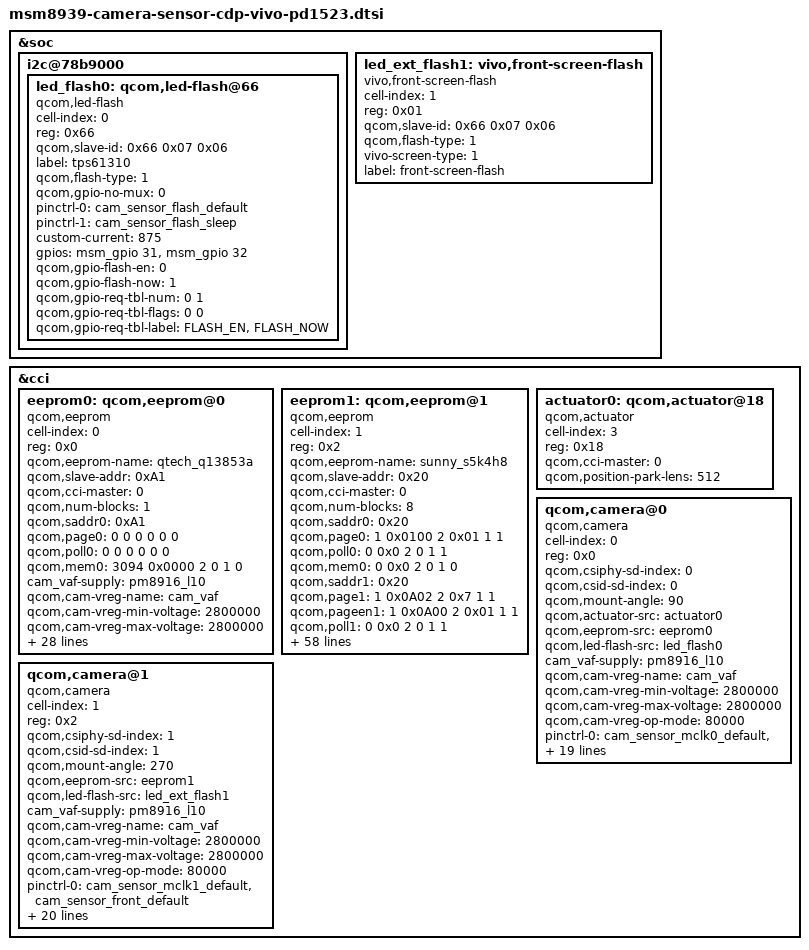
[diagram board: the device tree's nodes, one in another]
/*
 * Copyright (c) 2014, The Linux Foundation. All rights reserved.
 *
 * This program is free software; you can redistribute it and/or modify
 * it under the terms of the GNU General Public License version 2 and
 * only version 2 as published by the Free Software Foundation.
 *
 * This program is distributed in the hope that it will be useful,
 * but WITHOUT ANY WARRANTY; without even the implied warranty of
 * MERCHANTABILITY or FITNESS FOR A PARTICULAR PURPOSE.  See the
 * GNU General Public License for more details.
 */

&soc {
	i2c@78b9000 { /* BLSP1 QUP5 */
		status = "ok";
		led_flash0: qcom,led-flash@66 {
		    cell-index = <0>;
			reg = <0x66>;
			qcom,slave-id = <0x66 0x07 0x06>;
			compatible = "qcom,led-flash";
			label = "tps61310";
			/*qcom,flash-name = "tps61310";*/
			qcom,flash-type = <1>;
			qcom,gpio-no-mux = <0>;
			pinctrl-names = "cam_flash_default", "cam_flash_suspend";
			pinctrl-0 = <&cam_sensor_flash_default>;
			pinctrl-1 = <&cam_sensor_flash_sleep>;
			
			custom-current = <875>;
			gpios = <&msm_gpio 31 0>,<&msm_gpio 32 0>;
	        	qcom,gpio-flash-en = <0>;
			qcom,gpio-flash-now = <1>;
			qcom,gpio-req-tbl-num = <0 1>;
			qcom,gpio-req-tbl-flags = <0 0>;
			qcom,gpio-req-tbl-label = "FLASH_EN",
				"FLASH_NOW";
	    };	
	};
	led_ext_flash1: vivo,front-screen-flash {
		cell-index = <1>;
		reg = <0x01>;
        qcom,slave-id = <0x66 0x07 0x06>;
        qcom,flash-type = <1>;
        vivo-screen-type = <1>;
		compatible = "vivo,front-screen-flash";
		label = "front-screen-flash";
	};	
};


&cci {

	//add by panchenjun 
	
eeprom0: qcom,eeprom@0{
		cell-index = <0>;
		reg = <0x0>; 
		qcom,eeprom-name = "qtech_q13853a"; 
		compatible = "qcom,eeprom";
		qcom,slave-addr = <0xA1>; 
		qcom,cci-master = <0>;
		qcom,num-blocks = <1>; 
		qcom,saddr0 = <0xA1>;
		qcom,page0 = <0 0 0 0 0 0>;
		qcom,poll0 = <0 0 0 0 0 0>;
		qcom,mem0 = <3094 0x0000 2 0 1 0>;//read module info

		cam_vaf-supply = <&pm8916_l10>;//not use,use gpio1;PS:vana also use gpio1	
		qcom,cam-vreg-name = "cam_vaf";		
		qcom,cam-vreg-min-voltage = <2800000>;		
		qcom,cam-vreg-max-voltage = <2800000>;		
		qcom,cam-vreg-op-mode = <100000>;		
		qcom,gpio-no-mux = <0>; 
		
		pinctrl-names = "cam_default", "cam_suspend";		
		pinctrl-0 = <&cam_sensor_mclk0_default	&cam_sensor_rear_default>;		
		pinctrl-1 = <&cam_sensor_mclk0_sleep 	&cam_sensor_rear_sleep>;
		
		gpios = <&msm_gpio 26 0>,
			<&msm_gpio 35 0>,
			<&msm_gpio 76 0>,
			<&msm_gpio 17 0>,
			<&msm_gpio 77 0>;
		qcom,gpio-reset = <1>;
		qcom,gpio-vana = <2>;
		qcom,gpio-vdig = <3>;
		qcom,gpio-vio = <4>;
		qcom,gpio-req-tbl-num = <0 1 2 3 4>;
		qcom,gpio-req-tbl-flags = <1 0 0 0 0>;
		qcom,gpio-req-tbl-label = "CAMIF_MCLK",
			"CAM_RESET",
			"CAM_VANA",
			"CAM_VDIG",
			"CAM_VIO";
		qcom,sensor-position = <0>;
		qcom,sensor-mode = <0>;
		qcom,cam-power-seq-delay = <5 5 5 5 10 >; 
		qcom,cam-power-seq-type = "sensor_gpio", "sensor_gpio", "sensor_vreg", "sensor_gpio", "sensor_clk";
		qcom,cam-power-seq-val = "sensor_gpio_vana",  "sensor_gpio_vio", "cam_vaf", "sensor_gpio_reset", "sensor_cam_mclk";
		qcom,cam-power-seq-cfg-val = <1 1  1 1 24000000>; 
		
		status = "ok";
		clocks = <&clock_gcc clk_mclk0_clk_src>,				
			<&clock_gcc clk_gcc_camss_mclk0_clk>;		
		clock-names = "cam_src_clk", "cam_clk";
			
	}; 	
	//add end
	//lianhua add for sub camera s5k4h8 
	eeprom1: qcom,eeprom@1 { 
		cell-index = <1>; 
		reg = <0x2>; 
		qcom,eeprom-name = "sunny_s5k4h8"; 
		compatible = "qcom,eeprom"; 

		qcom,slave-addr = <0x20>; 
		qcom,cci-master = <0>; 
		qcom,num-blocks = <8>; 
	

		qcom,saddr0 = <0x20>;
		qcom,page0 = <1 0x0100 2 0x01 1 1>;
		qcom,poll0= <0 0x0 2 0 1 1>;
		qcom,mem0 = <0 0x0 2 0 1 0>;

		qcom,saddr1 = <0x20>;
		qcom,page1 = <1 0x0A02 2 0x7 1 1>;  //page 0 module info
		qcom,pageen1 = <1 0x0A00 2 0x01 1 1>;
		qcom,poll1 = <0 0x0 2 0 1 1>;
		qcom,mem1= <59 0x0A09 2 0 1 0>;

		qcom,saddr2 = <0x20>;
		qcom,page2 = <1 0x0A02 2 0x8 1 1>;  //page 0 module info
		qcom,pageen2 = <1 0x0A00 2 0x01 1 1>;
		qcom,poll2= <0 0x0 2 0 1 1>;
		qcom,mem2= <64 0x0A04 2 0 1 0>;


		qcom,saddr3 = <0x20>;
		qcom,page3= <1 0x0A02 2 0x9 1 1>;  //page 0 module info
		qcom,pageen3 = <1 0x0A00 2 0x01 1 1>;
		qcom,poll3 = <0 0x0 2 0 1 1>;
		qcom,mem3 = <64 0x0A04 2 0 1 0>;

		
		qcom,saddr4 = <0x20>;
		qcom,page4 = <1 0x0A02 2 0xa 1 1>;  //page 0 module info
		qcom,pageen4 = <1 0x0A00 2 0x01 1 1>;
		qcom,poll4 = <0 0x0 2 0 1 1>;
		qcom,mem4 = <64 0x0A04 2 0 1 0>;

		
		qcom,saddr5 = <0x20>;
		qcom,page5 = <1 0x0A02 2 0xb 1 1>;  //page 0 module info
		qcom,pageen5 = <1 0x0A00 2 0x01 1 1>;
		qcom,poll5 = <0 0x0 2 0 1 1>;
		qcom,mem5 = <64 0x0A04 2 0 1 0>;

		
		qcom,saddr6 = <0x20>;
		qcom,page6 = <1 0x0A02 2 0xc 1 1>;  //page 0 module info
		qcom,pageen6 = <1 0x0A00 2 0x01 1 1>;
		qcom,poll6 = <0 0x0 2 0 1 1>;
		qcom,mem6 = <44 0x0A04 2 0 1 0>;

		
		qcom,saddr7 = <0x20>;
		qcom,page7 = <1 0x0A02 2 0xf 1 1>;  //page 0 module info
		qcom,pageen7 = <1 0x0A00 2 0x01 1 1>;
		qcom,poll7 = <0 0x0 2 0 1 1>;
		qcom,mem7 = <64 0x0A04 2 0 1 0>;
		
		pinctrl-names = "cam_default", "cam_suspend";
		pinctrl-0 = <&cam_sensor_mclk1_default &cam_sensor_front_default
				>;
		pinctrl-1 = <&cam_sensor_mclk1_sleep &cam_sensor_front_sleep
				>;
		gpios = <&msm_gpio 27 0>,
			<&msm_gpio 28 0>,
			<&msm_gpio 33 0>,
			<&msm_gpio 76 0>,
			<&msm_gpio 0 0>,
			<&msm_gpio 77 0>;
		qcom,gpio-reset = <1>;
		qcom,gpio-standby = <2>;
		qcom,gpio-vana = <3>;
		qcom,gpio-vdig = <4>;
		qcom,gpio-vio = <5>;
		qcom,gpio-req-tbl-num = <0 1 2 3 4 5>;
		qcom,gpio-req-tbl-flags = <1 0 0 0 0 0>;
		qcom,gpio-req-tbl-label = "CAMIF_MCLK",
			"CAM_RESET",
			"CAM_STANDBY",
			"CAM_VANA1",
			"CAM_VDIG",
			"CAM_VIO";
		
		qcom,cam-power-seq-type ="sensor_gpio", "sensor_gpio",	"sensor_gpio", 
		"sensor_gpio","sensor_clk"; 
		qcom,cam-power-seq-val ="sensor_gpio_vio", "sensor_gpio_vana","sensor_gpio_vdig",  
		"sensor_gpio_reset","sensor_cam_mclk"; 
		
		qcom,cam-power-seq-cfg-val = <1 1 1 1 24000000 >; 
		qcom,cam-power-seq-delay = <5 5 5 5 5 >; 
		
		status = "ok";
		qcom,mclk-24000000;
		clocks = <&clock_gcc clk_mclk1_clk_src>,
				<&clock_gcc clk_gcc_camss_mclk1_clk>;
		clock-names = "cam_src_clk", "cam_clk";

	}; 	


	actuator0: qcom,actuator@18 {
		cell-index = <3>;
		reg = <0x18>;
		compatible = "qcom,actuator";
		qcom,cci-master = <0>;
		qcom,position-park-lens = <512>;
		/*
		cam_vaf-supply = <&pm8916_l10>;
		qcom,cam-vreg-name = "cam_vaf";
		qcom,cam-vreg-min-voltage = <2800000>;
		qcom,cam-vreg-max-voltage = <2800000>;
		qcom,cam-vreg-op-mode = <80000>;
		*/
	};


	qcom,camera@0{
		cell-index = <0>;
		compatible = "qcom,camera";
		reg = <0x0>;
		qcom,csiphy-sd-index = <0>;
		qcom,csid-sd-index = <0>;
		qcom,mount-angle = <90>;
		qcom,actuator-src = <&actuator0>;
		qcom,eeprom-src = <&eeprom0>; 
		qcom,led-flash-src = <&led_flash0>;
		cam_vaf-supply = <&pm8916_l10>;
		qcom,cam-vreg-name = "cam_vaf";
		qcom,cam-vreg-min-voltage = <2800000>;
		qcom,cam-vreg-max-voltage = <2800000>;
		qcom,cam-vreg-op-mode = <80000>;
		pinctrl-names = "cam_default", "cam_suspend";
		pinctrl-0 = <&cam_sensor_mclk0_default
					&cam_sensor_rear_default>;
		pinctrl-1 = <&cam_sensor_mclk0_sleep &cam_sensor_rear_sleep>;
		gpios = <&msm_gpio 26 0>,
			<&msm_gpio 35 0>,
			<&msm_gpio 76 0>,
			<&msm_gpio 17 0>,
			<&msm_gpio 77 0>;
		qcom,gpio-reset = <1>;
		qcom,gpio-vana = <2>;
		qcom,gpio-vdig = <3>;
		qcom,gpio-vio = <4>;
		qcom,gpio-req-tbl-num = <0 1 2 3 4>;
		qcom,gpio-req-tbl-flags = <1 0 0 0 0>;
		qcom,gpio-req-tbl-label = "CAMIF_MCLK",
			"CAM_RESET",
			"CAM_VANA",
			"CAM_VDIG",
			"CAM_VIO";
		qcom,sensor-position = <0>;
		qcom,sensor-mode = <0>;
		qcom,cci-master = <0>;
		qcom,mclk-24000000;
		status = "ok";
		clocks = <&clock_gcc clk_mclk0_clk_src>,				
			<&clock_gcc clk_gcc_camss_mclk0_clk>;		
		clock-names = "cam_src_clk", "cam_clk";
	};

	//lianhua add for sub camera s5k4h8 
	
	qcom,camera@1 {
		cell-index = <1>;
		compatible = "qcom,camera";
		reg = <0x2>;
		qcom,csiphy-sd-index = <1>;
		qcom,csid-sd-index = <1>;
		qcom,mount-angle = <270>;
		qcom,eeprom-src = <&eeprom1>;
		qcom,led-flash-src = <&led_ext_flash1>;
	//	cam_vio-supply = <&pm8916_l16>;
	//	qcom,cam-vreg-name =  "cam_vio";
		//qcom,cam-vreg-type = <1>;
	//	qcom,cam-vreg-min-voltage = <1800000>;
	//	qcom,cam-vreg-max-voltage = <1800000>;
	//	qcom,cam-vreg-op-mode = <0>;
	       cam_vaf-supply = <&pm8916_l10>;
		qcom,cam-vreg-name = "cam_vaf";
		qcom,cam-vreg-min-voltage = <2800000>;
		qcom,cam-vreg-max-voltage = <2800000>;
		qcom,cam-vreg-op-mode = <80000>;
		
		pinctrl-names = "cam_default", "cam_suspend";
		pinctrl-0 = <&cam_sensor_mclk1_default &cam_sensor_front_default
				>;
		pinctrl-1 = <&cam_sensor_mclk1_sleep &cam_sensor_front_sleep
				>;
		gpios = <&msm_gpio 27 0>,
			<&msm_gpio 28 0>,
			<&msm_gpio 33 0>,
			<&msm_gpio 76 0>,
			<&msm_gpio 0 0>,
			<&msm_gpio 77 0>;
		qcom,gpio-reset = <1>;
		qcom,gpio-standby = <2>;
		qcom,gpio-vana = <3>;
		qcom,gpio-vdig = <4>;
		qcom,gpio-vio = <5>;
		qcom,gpio-req-tbl-num = <0 1 2 3 4 5>;
		qcom,gpio-req-tbl-flags = <1 0 0 0 0 0>;
		qcom,gpio-req-tbl-label = "CAMIF_MCLK",
			"CAM_RESET",
			"CAM_STANDBY",
			"CAM_VANA1",
			"CAM_VDIG",
			"CAM_VIO";
		qcom,sensor-position = <1>;		
		qcom,sensor-mode = <0>;		
		qcom,cci-master = <0>;
		qcom,mclk-24000000;
		status = "ok";
		clocks = <&clock_gcc clk_mclk1_clk_src>,
				<&clock_gcc clk_gcc_camss_mclk1_clk>;
		clock-names = "cam_src_clk", "cam_clk";
	};

};
